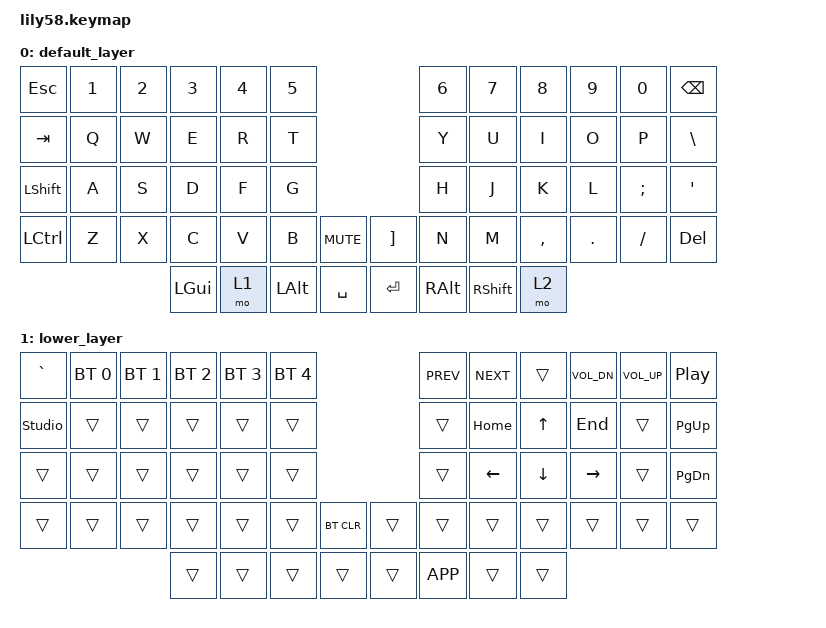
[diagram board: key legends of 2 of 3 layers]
/*
 * Copyright (c) 2020 The ZMK Contributors
 *
 * SPDX-License-Identifier: MIT
 */

#include <behaviors.dtsi>
#include <behaviors/studio_unlock.dtsi>
#include <dt-bindings/zmk/keys.h>
#include <dt-bindings/zmk/bt.h>
#include <dt-bindings/zmk/ext_power.h>

/ {
  keymap {
    compatible = "zmk,keymap";

    default_layer {
      bindings = <
&kp ESC   &kp N1 &kp N2 &kp N3   &kp N4   &kp N5                     &kp N6 &kp N7   &kp N8    &kp N9  &kp N0   &kp BSPC
&kp TAB   &kp Q  &kp W  &kp E    &kp R    &kp T                      &kp Y  &kp U    &kp I     &kp O   &kp P    &kp BSLH
&kp LSHFT &kp A  &kp S  &kp D    &kp F    &kp G                      &kp H  &kp J    &kp K     &kp L   &kp SEMI &kp SQT
&kp LCTRL &kp Z  &kp X  &kp C    &kp V    &kp B  &kp C_MUTE &kp RBKT &kp N  &kp M    &kp COMMA &kp DOT &kp FSLH &kp DEL
                        &kp LGUI &mo 1 &kp LALT   &kp SPACE  &kp RET &kp RALT &kp RSHFT &mo 2
      >;

      /* Encoders (requires 2-sensor overlay):
       * sensor 0 = encoder izquierdo  -> volumen
       * sensor 1 = encoder derecho    -> flechas arriba/abajo
       */
      sensor-bindings = <
        &inc_dec_kp C_VOL_UP C_VOL_DN
        &inc_dec_kp UP DOWN
      >;
    };

    lower_layer {
      bindings = <
&kp GRAVE &bt BT_SEL 0  &bt BT_SEL 1 &bt BT_SEL 2 &bt BT_SEL 3   &bt BT_SEL 4              &kp C_PREV        &kp C_NEXT        &trans         &kp C_VOL_DN     &kp C_VOL_UP     &kp C_PP
&studio_unlock &trans   &trans       &trans       &trans         &trans                     &trans            &kp HOME          &kp UP          &kp END         &trans           &kp PG_UP
&trans    &trans        &trans       &trans       &trans         &trans                     &trans            &kp LEFT          &kp DOWN        &kp RIGHT       &trans           &kp PG_DN
&trans    &trans        &trans       &trans       &trans         &trans         &bt BT_CLR  &trans            &trans            &trans          &trans           &trans          &trans          &trans
                                     &trans       &trans         &trans                      &trans            &trans            &kp K_APP        &trans          &trans
      >;

      sensor-bindings = <
        &inc_dec_kp C_VOL_UP C_VOL_DN
        &inc_dec_kp UP DOWN
      >;
    };

    raise_layer {
      bindings = <
&kp F1    &kp F2          &kp F3            &kp F4                &kp F5          &kp F6                              &kp F7    &kp F8    &kp F9      &kp F10      &kp F11       &kp F12
&trans    &trans          &trans            &trans                &trans          &trans                               &trans    &trans    &trans      &kp MINUS    &kp EQUAL     &trans
&trans    &trans          &trans            &trans                &trans          &trans                               &trans    &trans    &trans      &trans       &trans        &trans
&trans    &trans          &trans            &trans                &trans          &trans                               &trans    &trans    &trans      &trans       &trans        &trans
                                                 &trans           &trans          &trans          &trans              &trans    &trans    &trans      &trans
      >;

      sensor-bindings = <
        &inc_dec_kp C_VOL_UP C_VOL_DN
        &inc_dec_kp UP DOWN
      >;
    };
  };
};
